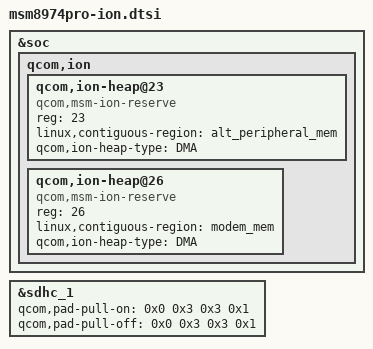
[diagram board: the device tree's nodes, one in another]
/* Copyright (c) 2013, The Linux Foundation. All rights reserved.
 *
 * This program is free software; you can redistribute it and/or modify
 * it under the terms of the GNU General Public License version 2 and
 * only version 2 as published by the Free Software Foundation.
 *
 * This program is distributed in the hope that it will be useful,
 * but WITHOUT ANY WARRANTY; without even the implied warranty of
 * MERCHANTABILITY or FITNESS FOR A PARTICULAR PURPOSE.  See the
 * GNU General Public License for more details.
 */

&soc {
	qcom,ion {

		qcom,ion-heap@23 { /* OTHER PIL HEAP */
			compatible = "qcom,msm-ion-reserve";
			reg = <23>;
			linux,contiguous-region = <&alt_peripheral_mem>;
			qcom,ion-heap-type = "DMA";
		};

		qcom,ion-heap@26 { /* MODEM HEAP */
			compatible = "qcom,msm-ion-reserve";
			reg = <26>;
			linux,contiguous-region = <&modem_mem>;
			qcom,ion-heap-type = "DMA";
		};
	};
};

&sdhc_1 {
	qcom,pad-pull-on = <0x0 0x3 0x3 0x1>; /* no-pull, pull-up, pull-up, pull-down */
	qcom,pad-pull-off = <0x0 0x3 0x3 0x1>; /* no-pull, pull-up, pull-up, pull-down */
};
